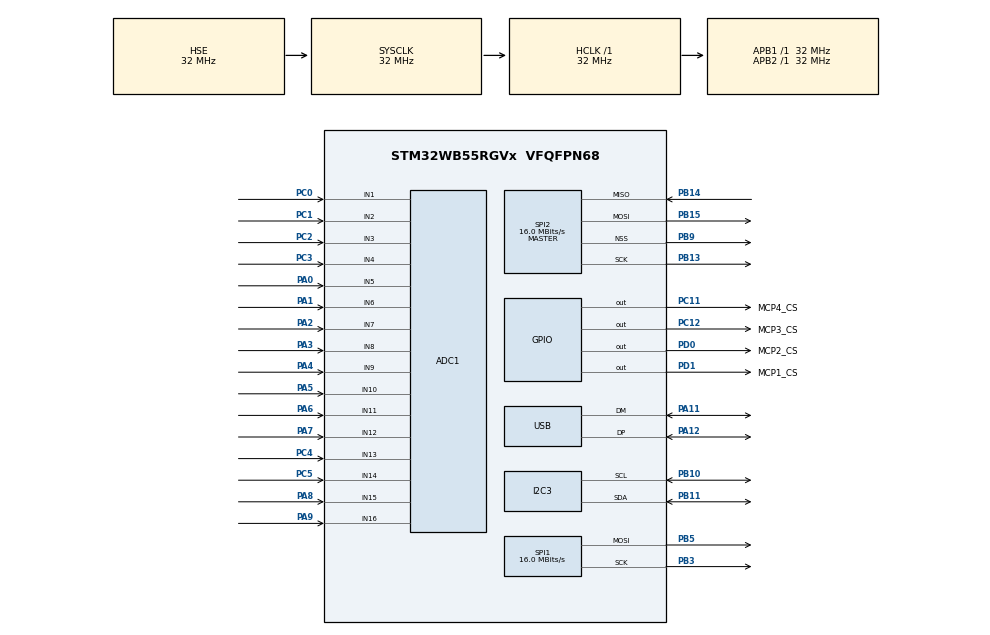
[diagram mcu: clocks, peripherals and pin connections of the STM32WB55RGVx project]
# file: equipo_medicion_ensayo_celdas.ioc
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ADC1.Channel-0\#ChannelRegularConversion=ADC_CHANNEL_1
ADC1.NbrOfConversionFlag=1
ADC1.OffsetNumber-0\#ChannelRegularConversion=ADC_OFFSET_NONE
ADC1.Rank-0\#ChannelRegularConversion=1
ADC1.SamplingTime-0\#ChannelRegularConversion=ADC_SAMPLETIME_2CYCLES_5
ADC1.master=1
FREERTOS.Tasks01=defaultTask,24,128,StartDefaultTask,Default,NULL,Dynamic,NULL,NULL
FREERTOS.configTOTAL_HEAP_SIZE=20480
FREERTOS.configUSE_TICKLESS_IDLE=0
I2C3.Timing=0x00B07CB4
Mcu.Family=STM32WB
Mcu.Name=STM32WB55RGVx
Mcu.Package=VFQFPN68
NVIC.HSEM_IRQn=true\:5\:0\:false\:false\:true\:true\:false\:true\:true
NVIC.IPCC_C1_RX_IRQn=true\:5\:0\:false\:false\:true\:true\:true\:true\:true
NVIC.IPCC_C1_TX_IRQn=true\:5\:0\:false\:false\:true\:true\:true\:true\:true
NVIC.PriorityGroup=NVIC_PRIORITYGROUP_4
NVIC.TIM1_TRG_COM_TIM17_IRQn=true\:15\:0\:false\:false\:true\:false\:false\:true\:true
NVIC.TimeBase=TIM1_TRG_COM_TIM17_IRQn
NVIC.TimeBaseIP=TIM17
NVIC.USB_LP_IRQn=true\:5\:0\:false\:false\:true\:true\:false\:true\:true
OSC_IN.Mode=HSE-External-Oscillator
OSC_IN.Signal=RCC_OSC_IN
OSC_OUT.Mode=HSE-External-Oscillator
OSC_OUT.Signal=RCC_OSC_OUT
PA0.Signal=ADCx_IN5
PA1.Signal=ADCx_IN6
PA11.Mode=Device
PA11.Signal=USB_DM
PA12.Mode=Device
PA12.Signal=USB_DP
PA2.Signal=ADCx_IN7
PA3.Signal=ADCx_IN8
PA4.Signal=ADCx_IN9
PA5.Signal=ADCx_IN10
PA6.Signal=ADCx_IN11
PA7.Signal=ADCx_IN12
PA8.Signal=ADCx_IN15
PA9.Signal=ADCx_IN16
PB10.Mode=I2C
PB10.Signal=I2C3_SCL
PB11.Mode=I2C
PB11.Signal=I2C3_SDA
PB13.Mode=Full_Duplex_Master
PB13.Signal=SPI2_SCK
PB14.Mode=Full_Duplex_Master
PB14.Signal=SPI2_MISO
PB15.Mode=Full_Duplex_Master
PB15.Signal=SPI2_MOSI
PB3.Mode=TX_Only_Simplex_Unidirect_Master
PB3.Signal=SPI1_SCK
PB5.Mode=TX_Only_Simplex_Unidirect_Master
PB5.Signal=SPI1_MOSI
PB9.Mode=NSS_Signal_Hard_Output
PB9.Signal=SPI2_NSS
PC0.Signal=ADCx_IN1
PC1.Signal=ADCx_IN2
PC11.GPIO_Label=MCP4_CS
PC11.Signal=GPIO_Output
PC12.GPIO_Label=MCP3_CS
PC12.Signal=GPIO_Output
PC14-OSC32_IN.Mode=LSE-External-Oscillator
PC14-OSC32_IN.Signal=RCC_OSC32_IN
PC15-OSC32_OUT.Mode=LSE-External-Oscillator
PC15-OSC32_OUT.Signal=RCC_OSC32_OUT
PC2.Signal=ADCx_IN3
PC3.Signal=ADCx_IN4
PC4.Signal=ADCx_IN13
PC5.Signal=ADCx_IN14
PD0.GPIO_Label=MCP2_CS
PD0.Signal=GPIO_Output
PD1.GPIO_Label=MCP1_CS
PD1.Signal=GPIO_Output
ProjectManager.HeapSize=0x200
ProjectManager.StackSize=0x400
ProjectManager.TargetToolchain=CMake
RCC.ADCFreq_Value=48000000
RCC.AHBFreq_Value=32000000
RCC.APB1Freq_Value=32000000
RCC.APB1TimFreq_Value=32000000
RCC.APB2Freq_Value=32000000
RCC.APB2TimFreq_Value=32000000
RCC.APB3Freq_Value=16000000
RCC.CortexFreq_Value=32000000
RCC.HCLKFreq_Value=32000000
RCC.HSE_VALUE=32000000
RCC.HSI48_VALUE=48000000
RCC.HSI_VALUE=16000000
RCC.PLLN=32
RCC.PLLSAI1N=24
RCC.SYSCLKFreq_VALUE=32000000
RCC.SYSCLKSource=RCC_SYSCLKSOURCE_HSE
RCC.USBFreq_Value=48000000
RCC.VCOOutputFreq_Value=128000000
RF1.Mode=RF1_Activate
RF1.Signal=RF_RF1
RTC.WakeUpClock-WakeUp=RTC_WAKEUPCLOCK_CK_SPRE_16BITS
SH.ADCx_IN1.0=ADC1_IN1,IN1-Single-Ended
SH.ADCx_IN10.0=ADC1_IN10,IN10-Single-Ended
SH.ADCx_IN11.0=ADC1_IN11,IN11-Single-Ended
SH.ADCx_IN12.0=ADC1_IN12,IN12-Single-Ended
SH.ADCx_IN13.0=ADC1_IN13,IN13-Single-Ended
SH.ADCx_IN14.0=ADC1_IN14,IN14-Single-Ended
SH.ADCx_IN15.0=ADC1_IN15,IN15-Single-Ended
SH.ADCx_IN16.0=ADC1_IN16,IN16-Single-Ended
SH.ADCx_IN2.0=ADC1_IN2,IN2-Single-Ended
SH.ADCx_IN3.0=ADC1_IN3,IN3-Single-Ended
SH.ADCx_IN4.0=ADC1_IN4,IN4-Single-Ended
SH.ADCx_IN5.0=ADC1_IN5,IN5-Single-Ended
SH.ADCx_IN6.0=ADC1_IN6,IN6-Single-Ended
SH.ADCx_IN7.0=ADC1_IN7,IN7-Single-Ended
SH.ADCx_IN8.0=ADC1_IN8,IN8-Single-Ended
SH.ADCx_IN9.0=ADC1_IN9,IN9-Single-Ended
SPI1.CalculateBaudRate=16.0 MBits/s
SPI1.Direction=SPI_DIRECTION_2LINES
SPI1.Mode=SPI_MODE_MASTER
SPI1.VirtualType=VM_MASTER
SPI2.CalculateBaudRate=16.0 MBits/s
SPI2.Direction=SPI_DIRECTION_2LINES
SPI2.Mode=SPI_MODE_MASTER
SPI2.VirtualNSS=VM_NSSHARD
SPI2.VirtualType=VM_MASTER
STM32_WPAN.BT_SIG_HEART_RATE_SENSOR=Disabled
USB_DEVICE.CLASS_NAME_FS=CDC
USB_DEVICE.VirtualMode=Cdc
USB_DEVICE.VirtualModeFS=Cdc_FS
VP_FREERTOS_VS_CMSIS_V2.Mode=CMSIS_V2
VP_HSEM_VS_HSEM.Mode=HSEM_Activate
VP_IPCC_VS_IPCC.Mode=IPCC_Activate
VP_MEMORYMAP_VS_MEMORYMAP.Mode=CurAppReg
VP_RTC_VS_RTC_Activate.Mode=RTC_Enabled
VP_RTC_VS_RTC_WakeUp_intern.Mode=WakeUp
VP_STM32_WPAN_VS_BLE_HOST.Mode=STM32_WPAN_Enabled
VP_SYS_VS_tim17.Mode=TIM17
VP_TINY_LPM_VS_TINY_LPM.Mode=TINY_LPM_Enabled
VP_USB_DEVICE_VS_USB_DEVICE_CDC_FS.Mode=CDC_FS
board=custom

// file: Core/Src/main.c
/* USER CODE BEGIN Header */
/**
  ******************************************************************************
  * @file           : main.c
  * @brief          : Main program body
  ******************************************************************************
  * @attention
  *
  * Copyright (c) 2026 STMicroelectronics.
  * All rights reserved.
  *
  * This software is licensed under terms that can be found in the LICENSE file
  * in the root directory of this software component.
  * If no LICENSE file comes with this software, it is provided AS-IS.
  *
  ******************************************************************************
  */
/* USER CODE END Header */
#include "main.h"
#include "cmsis_os2.h"
#include "FreeRTOS.h"
#include "adc.h"
#include "i2c.h"
#include "ipcc.h"
#include "rf.h"
#include "rtc.h"
#include "spi.h"
#include "usb_device.h"
#include "gpio.h"

void SystemClock_Config(void);
void PeriphCommonClock_Config(void);
void MX_FREERTOS_Init(void);

int main(void)
{

  /* MCU Configuration--------------------------------------------------------*/

  /* Reset of all peripherals, Initializes the Flash interface and the Systick. */
  HAL_Init();
  /* Config code for STM32_WPAN (HSE Tuning must be done before system clock configuration) */
  MX_APPE_Config();

  /* Configure the system clock */
  SystemClock_Config();

  /* Configure the peripherals common clocks */
  PeriphCommonClock_Config();

  /* IPCC initialisation */
  MX_IPCC_Init();

  /* Initialize all configured peripherals */
  MX_GPIO_Init();
  MX_ADC1_Init();
  MX_I2C3_Init();
  MX_RTC_Init();
  MX_SPI1_Init();
  MX_SPI2_Init();
  MX_RF_Init();

  /* Init scheduler */
  osKernelInitialize();
  /* Init code for STM32_WPAN */
  MX_APPE_Init();
  /* Call init function for freertos objects (in cmsis_os2.c) */
  MX_FREERTOS_Init();

  /* Start scheduler */
  osKernelStart();

  /* We should never get here as control is now taken by the scheduler */

  /* Infinite loop */
  while (1)
  {

  }
}

void SystemClock_Config(void)
{
  RCC_OscInitTypeDef RCC_OscInitStruct = {0};
  RCC_ClkInitTypeDef RCC_ClkInitStruct = {0};

  /** Macro to configure the PLL multiplication factor
  */
  __HAL_RCC_PLL_PLLM_CONFIG(RCC_PLLM_DIV1);

  /** Macro to configure the PLL clock source
  */
  __HAL_RCC_PLL_PLLSOURCE_CONFIG(RCC_PLLSOURCE_MSI);

  /** Configure LSE Drive Capability
  */
  HAL_PWR_EnableBkUpAccess();
  __HAL_RCC_LSEDRIVE_CONFIG(RCC_LSEDRIVE_MEDIUMHIGH);

  /** Configure the main internal regulator output voltage
  */
  __HAL_PWR_VOLTAGESCALING_CONFIG(PWR_REGULATOR_VOLTAGE_SCALE1);

  /** Initializes the RCC Oscillators according to the specified parameters
  * in the RCC_OscInitTypeDef structure.
  */
  RCC_OscInitStruct.OscillatorType = RCC_OSCILLATORTYPE_HSI|RCC_OSCILLATORTYPE_LSI1
                              |RCC_OSCILLATORTYPE_HSE|RCC_OSCILLATORTYPE_LSE
                              |RCC_OSCILLATORTYPE_MSI;
  RCC_OscInitStruct.HSEState = RCC_HSE_ON;
  RCC_OscInitStruct.LSEState = RCC_LSE_ON;
  RCC_OscInitStruct.HSIState = RCC_HSI_ON;
  RCC_OscInitStruct.MSIState = RCC_MSI_ON;
  RCC_OscInitStruct.HSICalibrationValue = RCC_HSICALIBRATION_DEFAULT;
  RCC_OscInitStruct.MSICalibrationValue = RCC_MSICALIBRATION_DEFAULT;
  RCC_OscInitStruct.MSIClockRange = RCC_MSIRANGE_6;
  RCC_OscInitStruct.LSIState = RCC_LSI_ON;
  RCC_OscInitStruct.PLL.PLLState = RCC_PLL_NONE;
  if (HAL_RCC_OscConfig(&RCC_OscInitStruct) != HAL_OK)
  {
    Error_Handler();
  }

  /** Configure the SYSCLKSource, HCLK, PCLK1 and PCLK2 clocks dividers
  */
  RCC_ClkInitStruct.ClockType = RCC_CLOCKTYPE_HCLK4|RCC_CLOCKTYPE_HCLK2
                              |RCC_CLOCKTYPE_HCLK|RCC_CLOCKTYPE_SYSCLK
                              |RCC_CLOCKTYPE_PCLK1|RCC_CLOCKTYPE_PCLK2;
  RCC_ClkInitStruct.SYSCLKSource = RCC_SYSCLKSOURCE_HSE;
  RCC_ClkInitStruct.AHBCLKDivider = RCC_SYSCLK_DIV1;
  RCC_ClkInitStruct.APB1CLKDivider = RCC_HCLK_DIV1;
  RCC_ClkInitStruct.APB2CLKDivider = RCC_HCLK_DIV1;
  RCC_ClkInitStruct.AHBCLK2Divider = RCC_SYSCLK_DIV1;
  RCC_ClkInitStruct.AHBCLK4Divider = RCC_SYSCLK_DIV1;

  if (HAL_RCC_ClockConfig(&RCC_ClkInitStruct, FLASH_LATENCY_1) != HAL_OK)
  {
    Error_Handler();
  }

  /** Enable MSI Auto calibration
  */
  HAL_RCCEx_EnableMSIPLLMode();
}

void PeriphCommonClock_Config(void)
{
  RCC_PeriphCLKInitTypeDef PeriphClkInitStruct = {0};

  /** Initializes the peripherals clock
  */
  PeriphClkInitStruct.PeriphClockSelection = RCC_PERIPHCLK_SMPS|RCC_PERIPHCLK_RFWAKEUP
                              |RCC_PERIPHCLK_USB|RCC_PERIPHCLK_ADC;
  PeriphClkInitStruct.PLLSAI1.PLLN = 24;
  PeriphClkInitStruct.PLLSAI1.PLLP = RCC_PLLP_DIV2;
  PeriphClkInitStruct.PLLSAI1.PLLQ = RCC_PLLQ_DIV2;
  PeriphClkInitStruct.PLLSAI1.PLLR = RCC_PLLR_DIV2;
  PeriphClkInitStruct.PLLSAI1.PLLSAI1ClockOut = RCC_PLLSAI1_USBCLK|RCC_PLLSAI1_ADCCLK;
  PeriphClkInitStruct.UsbClockSelection = RCC_USBCLKSOURCE_PLLSAI1;
  PeriphClkInitStruct.AdcClockSelection = RCC_ADCCLKSOURCE_PLLSAI1;
  PeriphClkInitStruct.RFWakeUpClockSelection = RCC_RFWKPCLKSOURCE_HSE_DIV1024;
  PeriphClkInitStruct.SmpsClockSelection = RCC_SMPSCLKSOURCE_HSI;
  PeriphClkInitStruct.SmpsDivSelection = RCC_SMPSCLKDIV_RANGE1;

  if (HAL_RCCEx_PeriphCLKConfig(&PeriphClkInitStruct) != HAL_OK)
  {
    Error_Handler();
  }
}

void HAL_TIM_PeriodElapsedCallback(TIM_HandleTypeDef *htim)
{
  if (htim->Instance == TIM17)
  {
    HAL_IncTick();
  }
}

void Error_Handler(void)
{
  __disable_irq();
  while (1)
  {
  }
}

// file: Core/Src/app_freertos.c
/* USER CODE BEGIN Header */
/**
  ******************************************************************************
  * File Name          : app_freertos.c
  * Description        : Code for freertos applications
  ******************************************************************************
  * @attention
  *
  * Copyright (c) 2026 STMicroelectronics.
  * All rights reserved.
  *
  * This software is licensed under terms that can be found in the LICENSE file
  * in the root directory of this software component.
  * If no LICENSE file comes with this software, it is provided AS-IS.
  *
  ******************************************************************************
  */
/* USER CODE END Header */

#include "FreeRTOS.h"
#include "task.h"
#include "main.h"
#include "cmsis_os2.h"
#include "FreeRTOS.h"

/* USER CODE BEGIN Includes */
#include "usb_device.h"
/* USER CODE END Includes */

/* Definitions for defaultTask */
osThreadId_t defaultTaskHandle;
const osThreadAttr_t defaultTask_attributes = {
  .name = "defaultTask",
  .priority = (osPriority_t) osPriorityNormal,
  .stack_size = 128 * 4
};

void StartDefaultTask(void *argument);

void MX_FREERTOS_Init(void); /* (MISRA C 2004 rule 8.1) */

void MX_FREERTOS_Init(void) {

  /* Create the thread(s) */
  /* creation of defaultTask */
  defaultTaskHandle = osThreadNew(StartDefaultTask, NULL, &defaultTask_attributes);

}

void StartDefaultTask(void *argument)
{
  /* init code for USB_Device */
  MX_USB_Device_Init();
  for(;;)
  {
    osDelay(1);
  }
}
